# haltium_radiocore register map
Vendor: Nordic Semiconductor; Series: nRFHaltium; File version: 1
CPU: CM33 r0p4, little endian, MPU, FPU, 3 interrupt priority bits, 480 interrupts
Registers are 32-bit, read-write, reset 0x0 unless marked. A register's access mark holds for its fields unless they carry their own. Offsets are from the block's base; [hi:lo] are bit positions; 'fields as' and 'values as' point back to an identical list.

## GLOBAL_TSGEN_NS — GENERIC
Base 0xBF041000
Same registers: GLOBAL_ETB_NS 0xBF044000, GLOBAL_ETR_NS 0xBF045000
0x00 TASKS_GENERICTASK wo — Generic event
  [0] TASKS_GENERICTASK
    1=Trigger task
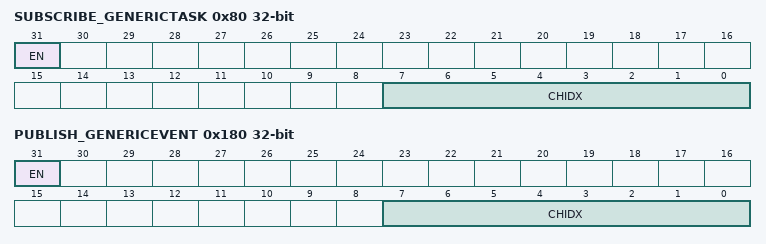
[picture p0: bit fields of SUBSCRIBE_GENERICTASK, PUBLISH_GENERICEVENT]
0x80 SUBSCRIBE_GENERICTASK — Subscribe configuration for task GENERICTASK
  [31] EN
    0=Disabled (Disable subscription); 1=Enabled (Enable subscription)
  [7:0] CHIDX — DPPI channel that task GENERICTASK will subscribe to
0x100 EVENTS_GENERICEVENT — Generic event
  [0] EVENTS_GENERICEVENT
    0=NotGenerated (Event not generated); 1=Generated (Event generated)
0x180 PUBLISH_GENERICEVENT — Publish configuration for event GENERICEVENT
  [31] EN
    0=Disabled (Disable publishing); 1=Enabled (Enable publishing)
  [7:0] CHIDX — DPPI channel that event GENERICEVENT will publish to
0x300 INTEN — Enable or disable interrupt
  [0] GENERICEVENT — Enable or disable interrupt for event GENERICEVENT
    0=Disabled; 1=Enabled
0x304 INTENSET — Enable interrupt
  [0] GENERICEVENT — Write '1' to enable interrupt for event GENERICEVENT
    on read: 0=Disabled (Read: Disabled); 1=Enabled (Read: Enabled) | on write: 1=Set (Enable)
0x308 INTENCLR — Disable interrupt
  [0] GENERICEVENT — Write '1' to disable interrupt for event GENERICEVENT
    on read: 0=Disabled (Read: Disabled); 1=Enabled (Read: Enabled) | on write: 1=Clear (Disable)

## CPUC_S — CM33 SubSystem
Base 0xE0080000
0x100 EVENTS_FPUIOC — An invalid operation exception has occurred in the FPU.
  [0] EVENTS_FPUIOC
    0=NotGenerated (Event not generated); 1=Generated (Event generated)
0x104 EVENTS_FPUDZC — A floating-point divide-by-zero exception has occurred in the FPU.
  [0] EVENTS_FPUDZC
    values as EVENTS_FPUIOC.EVENTS_FPUIOC
0x108 EVENTS_FPUOFC — A floating-point overflow exception has occurred in the FPU.
  [0] EVENTS_FPUOFC
    values as EVENTS_FPUIOC.EVENTS_FPUIOC
0x10C EVENTS_FPUUFC — A floating-point underflow exception has occurred in the FPU.
  [0] EVENTS_FPUUFC
    values as EVENTS_FPUIOC.EVENTS_FPUIOC
0x110 EVENTS_FPUIXC — A floating-point inexact exception has occurred in the FPU.
  [0] EVENTS_FPUIXC
    values as EVENTS_FPUIOC.EVENTS_FPUIOC
0x114 EVENTS_FPUIDC — A floating-point input denormal exception has occurred in the FPU.
  [0] EVENTS_FPUIDC
    values as EVENTS_FPUIOC.EVENTS_FPUIOC
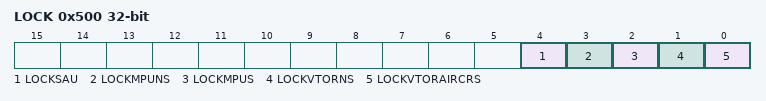
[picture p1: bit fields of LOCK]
0x500 LOCK — Register to lock the certain parts of the CPU from being modified.
  [4] LOCKSAU — Locks the Security Attribution Unit (SAU)
    0=NotLocked (SAU registers can be changed.); 1=Locked (Prevents changes to SAU registers.)
  [3] LOCKMPUNS — Locks the Memory Protection Unit (MPU) for non secure mode.
    0=NotLocked (MPU registers can be changed.); 1=Locked (Prevents changes to MPU registers.)
  [2] LOCKMPUS — Locks the Memory Protection Unit (MPU) for secure mode.
    values as LOCKMPUNS
  [1] LOCKVTORNS — Locks the Vector table Offset Register (VTOR) for non-secure mode.
    0=NotLocked (VTOR can be changed.); 1=Locked (Prevents changes to VTOR.)
  [0] LOCKVTORAIRCRS — Locks both the Vector table Offset Register (VTOR) and Application Interrupt and Reset Control Register (AIRCR) for secure mode.
    0=NotLocked (Both VTOR and AIRCR can be changed.); 1=Locked (Prevents changes to both VTOR and AIRCR.)
0x504 CPUID ro — The identifier for the CPU in this subsystem.
  [31:0] CPUID — The CPU identifier.

## RAMC000_NS — RAM Controller 0
Base 0x43004000
Same registers: RAMC001_NS 0x43038000, RAMC000_S 0x53004000, RAMC001_S 0x53038000
0x500 WAITSTATES — Waitstates for read operations.
  [0] WAITSTATES — Number of waitstates for a read from the RAM.
0x600 SECBASE — Base address for secure access area.
  [31:0] ADDR — Base address
0x604 SECENABLE — Enable secure access restrictions.
  [0] ENABLE — Enable secure access restrictions
    0=Disable (Secure access restrictions disabled); 1=Enable (Secure access restrictions enabled)

## Notices in the file
Copyright (c) 2010 - 2021, Nordic Semiconductor ASA
All rights reserved.
Redistribution and use in source and binary forms, with or without modification,
are permitted provided that the following conditions are met:
1. Redistributions of source code must retain the above copyright notice, this
list of conditions and the following disclaimer.
2. Redistributions in binary form, except as embedded into a Nordic
Semiconductor ASA integrated circuit in a product or a software update for
such product, must reproduce the above copyright notice, this list of
conditions and the following disclaimer in the documentation and/or other
materials provided with the distribution.
3. Neither the name of Nordic Semiconductor ASA nor the names of its
contributors may be used to endorse or promote products derived from this
software without specific prior written permission.
4. This software, with or without modification, must only be used with a
Nordic Semiconductor ASA integrated circuit.
5. Any software provided in binary form under this license must not be reverse
engineered, decompiled, modified and/or disassembled.
THIS SOFTWARE IS PROVIDED BY NORDIC SEMICONDUCTOR ASA "AS IS" AND ANY EXPRESS
OR IMPLIED WARRANTIES, INCLUDING, BUT NOT LIMITED TO, THE IMPLIED WARRANTIES
OF MERCHANTABILITY, NONINFRINGEMENT, AND FITNESS FOR A PARTICULAR PURPOSE ARE
DISCLAIMED. IN NO EVENT SHALL NORDIC SEMICONDUCTOR ASA OR CONTRIBUTORS BE
LIABLE FOR ANY DIRECT, INDIRECT, INCIDENTAL, SPECIAL, EXEMPLARY, OR
CONSEQUENTIAL DAMAGES (INCLUDING, BUT NOT LIMITED TO, PROCUREMENT OF SUBSTITUTE
GOODS OR SERVICES; LOSS OF USE, DATA, OR PROFITS; OR BUSINESS INTERRUPTION)
HOWEVER CAUSED AND ON ANY THEORY OF LIABILITY, WHETHER IN CONTRACT, STRICT
LIABILITY, OR TORT (INCLUDING NEGLIGENCE OR OTHERWISE) ARISING IN ANY WAY OUT
OF THE USE OF THIS SOFTWARE, EVEN IF ADVISED OF THE POSSIBILITY OF SUCH DAMAGE.
